# headsail register map
Vendor: tuni.fi; File version: 1.0
Headsail system view
CPU: other r1p0, little endian, no MPU, no FPU, vendor SysTick, 2 interrupt priority bits
Registers are 32-bit, read-write, no defined reset value unless marked. A register's access mark holds for its fields unless they carry their own. Offsets are from the block's base; lines under a group give offsets from that group; [hi:lo] are bit positions; {n}, {i} and the like mark numbered series; 'fields as' and 'values as' point back to an identical list; <NAME> marks a mode.

## Memory map
0x100000000 sdram
0x170080000 C2C_parallel
0x180080000 C2C_serial
0x190080000 ram0
0x190280000 ram1
0x190480000 ram2
0x190680000 ram3
0x1FF400000 EthSSPadConf size 0x44
0x1FF400200 mdio_map0 size 0x1C
0x1FF400400 mdio_map1 size 0x1C
0x1FF700000 DLA size 0x68
0x1FF800000 DSP blocks up to offset 0x354 — Stores different status information about the core
0x1FF900000 SYSCTRL blocks up to offset 0x21000
0x1FFA00000 DMA0 blocks up to offset 0x240 — The Excel of Register Map can be found here. <https://tuni.sharepoint.com/:x:/r/sites/TG-SoC-Hub/_layouts/15/Doc.aspx?sourcedoc=%7B971A5DEF-758E-4A18-8EA3-0F3F2D60F0BB%7D&file=DMA_register_map.xlsx&action=default&mobileredirect=true&cid=419a13fc-9dbd-45b9-8f31-77899c555ace> DMA Sub System Document available in below link: <https://tuni.sharepoint.com/:w:/r/sites/TG-SoC-Hub/_layouts/15/Doc.aspx?sourcedoc=%7B9E9DFD0D-B0CA-436B-ABA0-57DB3B73560E%7D&file=DMA_Sub_System_Document.....docx&action=default&mobileredirect=true>
0x1FFA08000 DMA1 blocks up to offset 0x240 — The Excel of Register Map can be found here. <https://tuni.sharepoint.com/:x:/r/sites/TG-SoC-Hub/_layouts/15/Doc.aspx?sourcedoc=%7B971A5DEF-758E-4A18-8EA3-0F3F2D60F0BB%7D&file=DMA_register_map.xlsx&action=default&mobileredirect=true&cid=419a13fc-9dbd-45b9-8f31-77899c555ace> DMA Sub System Document available in below link: <https://tuni.sharepoint.com/:w:/r/sites/TG-SoC-Hub/_layouts/15/Doc.aspx?sourcedoc=%7B9E9DFD0D-B0CA-436B-ABA0-57DB3B73560E%7D&file=DMA_Sub_System_Document.....docx&action=default&mobileredirect=true>
0x1FFB00000 C2C_config size 0x40
0x1FFC00000 C2C_serial size 0x74
0x1FFD00000 sdram_cfg size 0x74
0x1FFE00000 HPC blocks up to offset 0x90000
0x1FFF00000 apb_uart0 size 0x8
0x1FFF01000 apb_uart1 size 0x8
0x1FFF02000 apb_spim0 size 0x2C
0x1FFF03000 apb_spim1 size 0x2C
0x1FFF04000 apb_gpio size 0x40
0x1FFF05000 apb_i2c size 0x18
0x1FFF06000 apb_sw_irq size 0xC
0x1FFF07000 apb_pad_conf_reg_array size 0x134

## DLA
Base 0x1FF700000
0x00 CTRL group
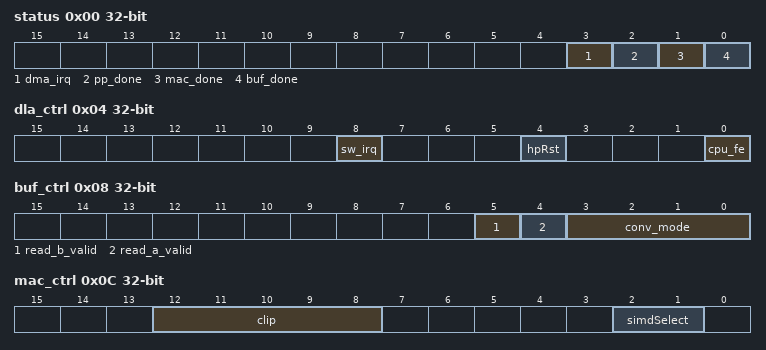
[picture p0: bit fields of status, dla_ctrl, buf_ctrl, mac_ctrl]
  0x00 status ro
    [3] dma_irq, [2] pp_done, [1] mac_done, [0] buf_done
  0x04 dla_ctrl
    [8] sw_irq, [4] hpRst, [0] cpu_fe
  0x08 buf_ctrl
    [5] read_b_valid, [4] read_a_valid, [3:0] conv_mode
  0x0C mac_ctrl
    [12:8] clip, [2:1] simdSelect
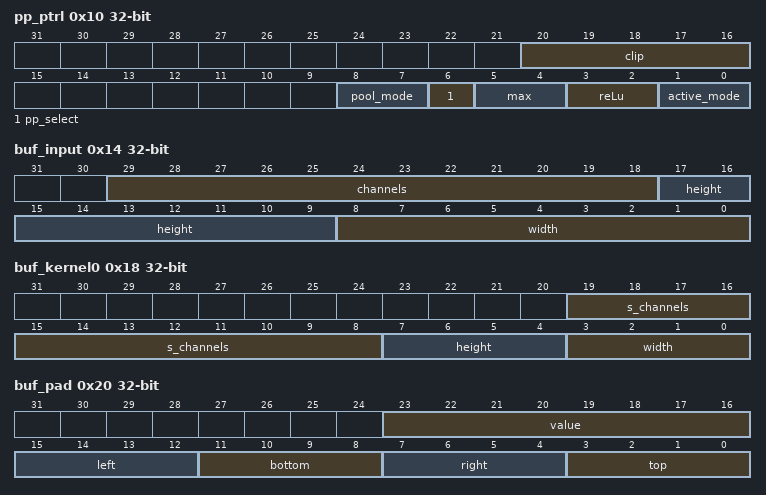
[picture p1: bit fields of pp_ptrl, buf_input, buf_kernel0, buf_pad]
  0x10 pp_ptrl
    [20:16] clip, [8:7] pool_mode, [6] pp_select, [5:4] max, [3:2] reLu, [1:0] active_mode
  0x14 buf_input
    [29:18] channels, [17:9] height, [8:0] width
  0x18 buf_kernel0
    [19:8] s_channels, [7:4] height, [3:0] width
  0x1C buf_kernel1
    [11:0] num
  0x20 buf_pad
    [23:16] value, [15:12] left, [11:8] bottom, [7:4] right, [3:0] top
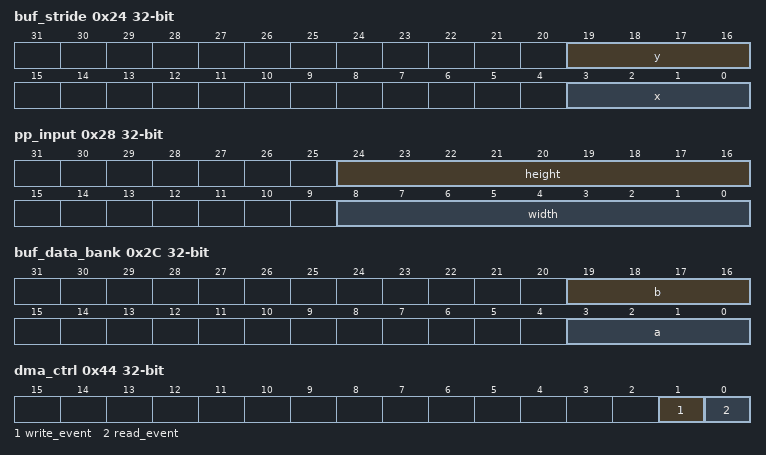
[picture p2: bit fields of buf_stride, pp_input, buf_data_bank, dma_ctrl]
  0x24 buf_stride
    [19:16] y, [3:0] x
  0x28 pp_input
    [24:16] height, [8:0] width
  0x2C buf_data_bank
    [19:16] b, [3:0] a
  0x30 buf_data_wait_a ro
    [31:0] data_a
  0x34 buf_data_wait_b ro
    [31:0] data_b
  0x38 buf_pipe_stall ro
    [31:0] cycles
  0x3C mac_data_b_wait ro
    [31:0] cycles
  0x40 mac_pipe_stall ro
    [31:0] cycles
  0x44 dma_ctrl
    [1] write_event, [0] read_event
  0x48 dma_pad ro
    [19:0] config
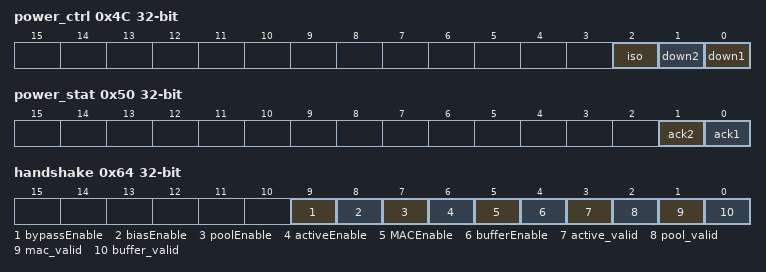
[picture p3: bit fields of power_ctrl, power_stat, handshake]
  0x4C power_ctrl
    [2] iso, [1] down2, [0] down1
  0x50 power_stat ro
    [1] ack2, [0] ack1
  0x54 mac_sat_max ro
    [31:0] maximum
  0x58 mac_sat_min ro
    [31:0] minimum
  0x5C pp_axi_write
    [31:0] addr
  0x60 pp_axi_read
    [31:0] addr
  0x64 handshake
    [9] bypassEnable, [8] biasEnable, [7] poolEnable, [6] activeEnable, [5] MACEnable, [4] bufferEnable, [3] active_valid, [2] pool_valid, [1] mac_valid, [0] buffer_valid
